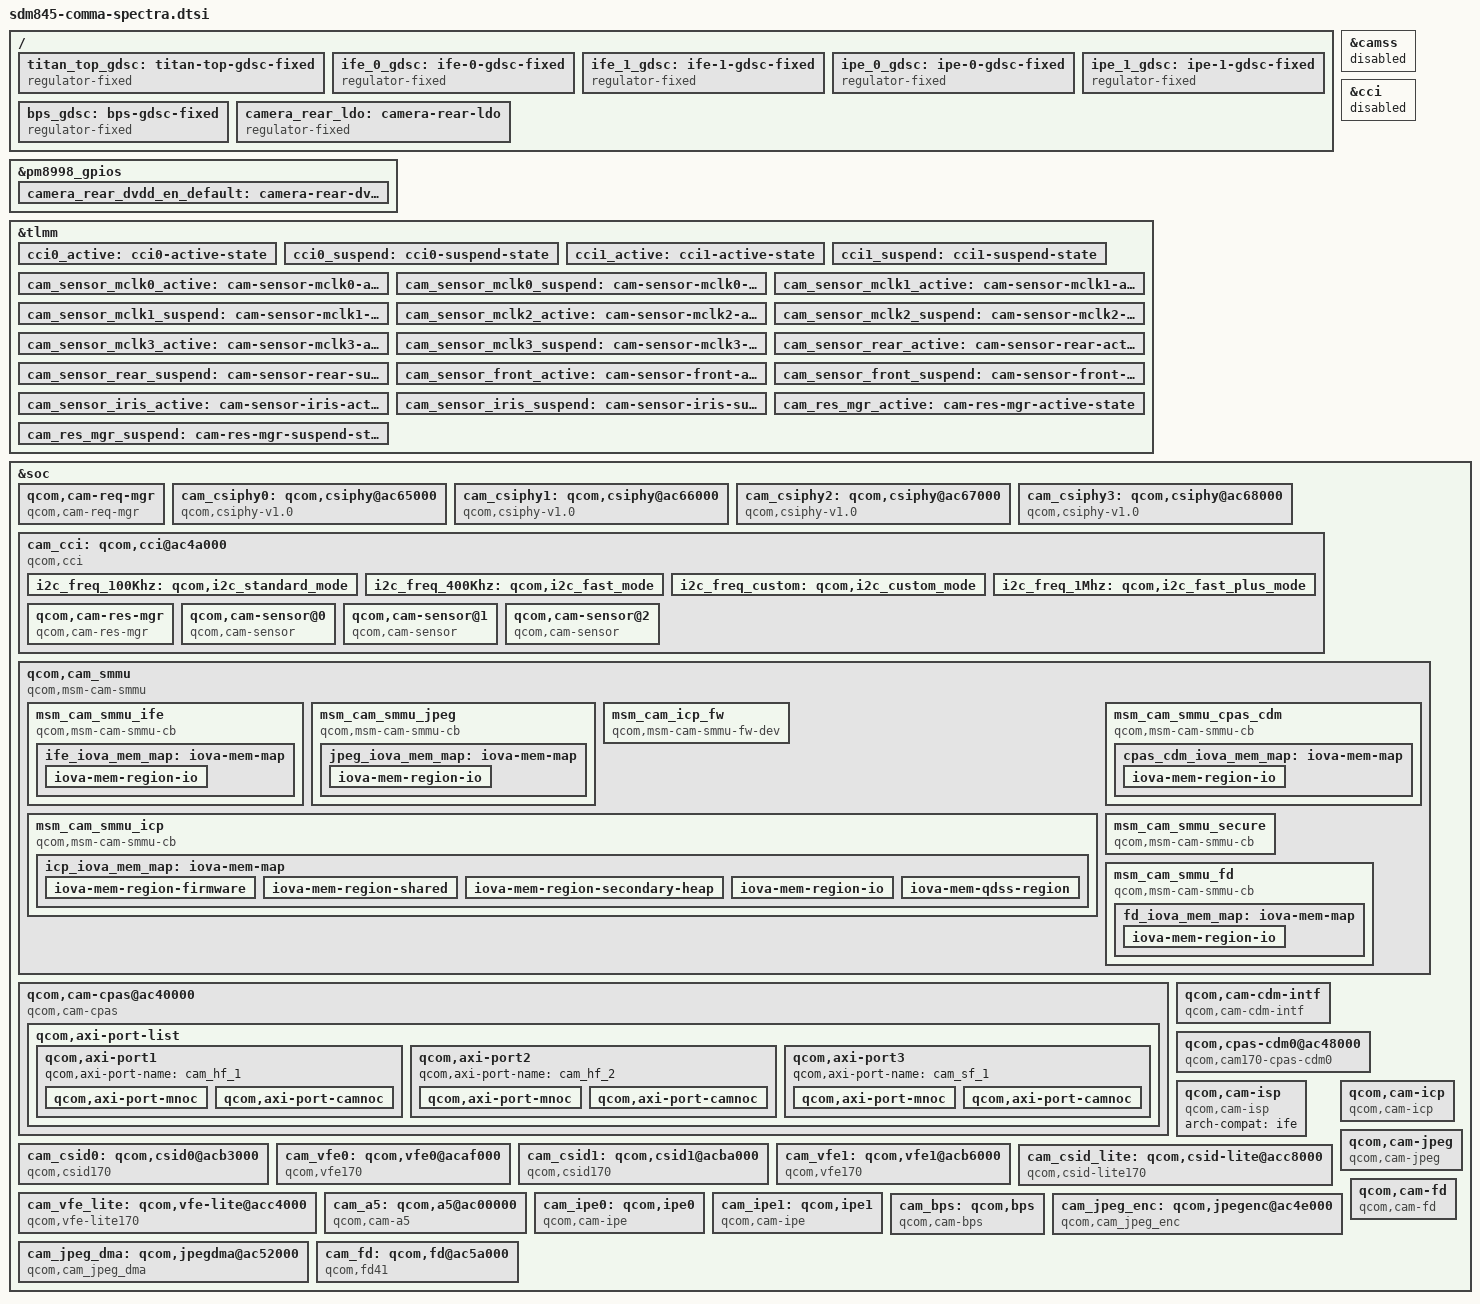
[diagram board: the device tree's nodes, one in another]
// SPDX-License-Identifier: GPL-2.0-only
// Camera-only nodes from cameras-spectra-mainline-andi, 391dedc767d9.

#include <dt-bindings/clock/qcom,camcc-sdm845.h>
#include <dt-bindings/clock/qcom,gcc-sdm845.h>
#include <dt-bindings/clock/qcom,rpmh.h>
#include <dt-bindings/gpio/gpio.h>
#include <dt-bindings/interconnect/qcom,icc.h>
#include <dt-bindings/interconnect/qcom,sdm845.h>
#include <dt-bindings/interrupt-controller/arm-gic.h>
#include <dt-bindings/pinctrl/qcom,pmic-gpio.h>

/ {
	titan_top_gdsc: titan-top-gdsc-fixed {
		compatible = "regulator-fixed";
		regulator-name = "titan_top_gdsc";
		regulator-always-on;
		regulator-boot-on;
	};

	ife_0_gdsc: ife-0-gdsc-fixed {
		compatible = "regulator-fixed";
		regulator-name = "ife_0_gdsc";
		regulator-always-on;
		regulator-boot-on;
	};

	ife_1_gdsc: ife-1-gdsc-fixed {
		compatible = "regulator-fixed";
		regulator-name = "ife_1_gdsc";
		regulator-always-on;
		regulator-boot-on;
	};

	ipe_0_gdsc: ipe-0-gdsc-fixed {
		compatible = "regulator-fixed";
		regulator-name = "ipe_0_gdsc";
		regulator-always-on;
		regulator-boot-on;
	};

	ipe_1_gdsc: ipe-1-gdsc-fixed {
		compatible = "regulator-fixed";
		regulator-name = "ipe_1_gdsc";
		regulator-always-on;
		regulator-boot-on;
	};

	bps_gdsc: bps-gdsc-fixed {
		compatible = "regulator-fixed";
		regulator-name = "bps_gdsc";
		regulator-always-on;
		regulator-boot-on;
	};

	camera_rear_ldo: camera-rear-ldo {
		compatible = "regulator-fixed";
		regulator-name = "camera_rear_ldo";
		regulator-min-microvolt = <1050000>;
		regulator-max-microvolt = <1050000>;
		gpio = <&pm8998_gpios 12 GPIO_ACTIVE_HIGH>;
		enable-active-high;
		pinctrl-names = "default";
		pinctrl-0 = <&camera_rear_dvdd_en_default>;
		regulator-always-on;
		regulator-boot-on;
	};






};
&camss {
	status = "disabled";
};

&cci {
	status = "disabled";
};

&pm8998_gpios {

	camera_rear_dvdd_en_default: camera-rear-dvdd-en-state {
		pins = "gpio12";
		function = "normal";
		bias-disable;
		drive-push-pull;
		qcom,drive-strength = <PMIC_GPIO_STRENGTH_HIGH>;
		output-high;
	};


};

&tlmm {
	cci0_active: cci0-active-state {
		pins = "gpio17", "gpio18";
		function = "cci_i2c";
		bias-pull-up;
		drive-strength = <2>;
	};

	cci0_suspend: cci0-suspend-state {
		pins = "gpio17", "gpio18";
		function = "cci_i2c";
		bias-pull-down;
		drive-strength = <2>;
	};

	cci1_active: cci1-active-state {
		pins = "gpio19", "gpio20";
		function = "cci_i2c";
		bias-pull-up;
		drive-strength = <2>;
	};

	cci1_suspend: cci1-suspend-state {
		pins = "gpio19", "gpio20";
		function = "cci_i2c";
		bias-pull-down;
		drive-strength = <2>;
	};

	cam_sensor_mclk0_active: cam-sensor-mclk0-active-state {
		pins = "gpio13";
		function = "cam_mclk";
		bias-disable;
		drive-strength = <8>;
	};

	cam_sensor_mclk0_suspend: cam-sensor-mclk0-suspend-state {
		pins = "gpio13";
		function = "cam_mclk";
		bias-pull-down;
		drive-strength = <8>;
	};

	cam_sensor_mclk1_active: cam-sensor-mclk1-active-state {
		pins = "gpio14";
		function = "cam_mclk";
		bias-disable;
		drive-strength = <8>;
	};

	cam_sensor_mclk1_suspend: cam-sensor-mclk1-suspend-state {
		pins = "gpio14";
		function = "cam_mclk";
		bias-pull-down;
		drive-strength = <8>;
	};

	cam_sensor_mclk2_active: cam-sensor-mclk2-active-state {
		pins = "gpio15";
		function = "cam_mclk";
		bias-disable;
		drive-strength = <8>;
	};

	cam_sensor_mclk2_suspend: cam-sensor-mclk2-suspend-state {
		pins = "gpio15";
		function = "cam_mclk";
		bias-pull-down;
		drive-strength = <8>;
	};

	cam_sensor_mclk3_active: cam-sensor-mclk3-active-state {
		pins = "gpio16";
		function = "cam_mclk";
		bias-disable;
		drive-strength = <2>;
	};

	cam_sensor_mclk3_suspend: cam-sensor-mclk3-suspend-state {
		pins = "gpio16";
		function = "cam_mclk";
		bias-pull-down;
		drive-strength = <2>;
	};

	cam_sensor_rear_active: cam-sensor-rear-active-state {
		pins = "gpio9";
		function = "gpio";
		bias-disable;
		drive-strength = <2>;
	};

	cam_sensor_rear_suspend: cam-sensor-rear-suspend-state {
		pins = "gpio9";
		function = "gpio";
		bias-pull-down;
		drive-strength = <2>;
		output-low;
	};

	cam_sensor_front_active: cam-sensor-front-active-state {
		pins = "gpio28";
		function = "gpio";
		bias-disable;
		drive-strength = <2>;
	};

	cam_sensor_front_suspend: cam-sensor-front-suspend-state {
		pins = "gpio28";
		function = "gpio";
		bias-pull-down;
		drive-strength = <2>;
		output-low;
	};

	cam_sensor_iris_active: cam-sensor-iris-active-state {
		pins = "gpio21";
		function = "gpio";
		bias-disable;
		drive-strength = <2>;
	};

	cam_sensor_iris_suspend: cam-sensor-iris-suspend-state {
		pins = "gpio21";
		function = "gpio";
		bias-pull-down;
		drive-strength = <2>;
		output-low;
	};

	cam_res_mgr_active: cam-res-mgr-active-state {
		pins = "gpio8";
		function = "gpio";
		bias-disable;
		drive-strength = <2>;
	};

	cam_res_mgr_suspend: cam-res-mgr-suspend-state {
		pins = "gpio8";
		function = "gpio";
		bias-disable;
		drive-strength = <2>;
		output-low;
	};
};

&soc {
	#address-cells = <2>;
	#size-cells = <2>;
	qcom,cam-req-mgr {
		compatible = "qcom,cam-req-mgr";
		status = "ok";
	};

	cam_csiphy0: qcom,csiphy@ac65000 {
		cell-index = <0>;
		compatible = "qcom,csiphy-v1.0", "qcom,csiphy";
		reg = <0 0x0ac65000 0 0x1000>;
		reg-names = "csiphy";
		reg-cam-base = <0x65000>;
		interrupts = <GIC_SPI 477 IRQ_TYPE_EDGE_RISING>;
		interrupt-names = "csiphy";
		gdscr-supply = <&titan_top_gdsc>;
		regulator-names = "gdscr";
		csi-vdd-voltage = <1200000>;
		mipi-csi-vdd-supply = <&vreg_l1a_0p875>;
		clocks = <&clock_camcc CAM_CC_CAMNOC_AXI_CLK>,
			<&clock_camcc CAM_CC_SOC_AHB_CLK>,
			<&clock_camcc CAM_CC_SLOW_AHB_CLK_SRC>,
			<&clock_camcc CAM_CC_CPAS_AHB_CLK>,
			<&clock_camcc CAM_CC_CPHY_RX_CLK_SRC>,
			<&clock_camcc CAM_CC_CSIPHY0_CLK>,
			<&clock_camcc CAM_CC_CSI0PHYTIMER_CLK_SRC>,
			<&clock_camcc CAM_CC_CSI0PHYTIMER_CLK>;
		clock-names = "camnoc_axi_clk",
			"soc_ahb_clk",
			"slow_ahb_src_clk",
			"cpas_ahb_clk",
			"cphy_rx_clk_src",
			"csiphy0_clk",
			"csi0phytimer_clk_src",
			"csi0phytimer_clk";
		src-clock-name = "csi0phytimer_clk_src";
		clock-cntl-level = "svs", "turbo";
		clock-rates =
			<0 0 0 0 320000000 0 269333333 0>,
			<0 0 0 0 384000000 0 269333333 0>;
		status = "ok";
	};

	cam_csiphy1: qcom,csiphy@ac66000 {
		cell-index = <1>;
		compatible = "qcom,csiphy-v1.0", "qcom,csiphy";
		reg = <0 0x0ac66000 0 0x1000>;
		reg-names = "csiphy";
		reg-cam-base = <0x66000>;
		interrupts = <GIC_SPI 478 IRQ_TYPE_EDGE_RISING>;
		interrupt-names = "csiphy";
		gdscr-supply = <&titan_top_gdsc>;
		regulator-names = "gdscr";
		csi-vdd-voltage = <1200000>;
		mipi-csi-vdd-supply = <&vreg_l1a_0p875>;
		clocks = <&clock_camcc CAM_CC_CAMNOC_AXI_CLK>,
			<&clock_camcc CAM_CC_SOC_AHB_CLK>,
			<&clock_camcc CAM_CC_SLOW_AHB_CLK_SRC>,
			<&clock_camcc CAM_CC_CPAS_AHB_CLK>,
			<&clock_camcc CAM_CC_CPHY_RX_CLK_SRC>,
			<&clock_camcc CAM_CC_CSIPHY1_CLK>,
			<&clock_camcc CAM_CC_CSI1PHYTIMER_CLK_SRC>,
			<&clock_camcc CAM_CC_CSI1PHYTIMER_CLK>;
		clock-names = "camnoc_axi_clk",
			"soc_ahb_clk",
			"slow_ahb_src_clk",
			"cpas_ahb_clk",
			"cphy_rx_clk_src",
			"csiphy1_clk",
			"csi1phytimer_clk_src",
			"csi1phytimer_clk";
		src-clock-name = "csi1phytimer_clk_src";
		clock-cntl-level = "svs", "turbo";
		clock-rates =
			<0 0 0 0 320000000 0 269333333 0>,
			<0 0 0 0 384000000 0 269333333 0>;
		status = "ok";
	};

	cam_csiphy2: qcom,csiphy@ac67000 {
		cell-index = <2>;
		compatible = "qcom,csiphy-v1.0", "qcom,csiphy";
		reg = <0 0x0ac67000 0 0x1000>;
		reg-names = "csiphy";
		reg-cam-base = <0x67000>;
		interrupts = <GIC_SPI 479 IRQ_TYPE_EDGE_RISING>;
		interrupt-names = "csiphy";
		gdscr-supply = <&titan_top_gdsc>;
		regulator-names = "gdscr";
		csi-vdd-voltage = <1200000>;
		mipi-csi-vdd-supply = <&vreg_l1a_0p875>;
		clocks = <&clock_camcc CAM_CC_CAMNOC_AXI_CLK>,
			<&clock_camcc CAM_CC_SOC_AHB_CLK>,
			<&clock_camcc CAM_CC_SLOW_AHB_CLK_SRC>,
			<&clock_camcc CAM_CC_CPAS_AHB_CLK>,
			<&clock_camcc CAM_CC_CPHY_RX_CLK_SRC>,
			<&clock_camcc CAM_CC_CSIPHY2_CLK>,
			<&clock_camcc CAM_CC_CSI2PHYTIMER_CLK_SRC>,
			<&clock_camcc CAM_CC_CSI2PHYTIMER_CLK>;
		clock-names = "camnoc_axi_clk",
			"soc_ahb_clk",
			"slow_ahb_src_clk",
			"cpas_ahb_clk",
			"cphy_rx_clk_src",
			"csiphy2_clk",
			"csi2phytimer_clk_src",
			"csi2phytimer_clk";
		src-clock-name = "csi2phytimer_clk_src";
		clock-cntl-level = "svs", "turbo";
		clock-rates =
			<0 0 0 0 320000000 0 269333333 0>,
			<0 0 0 0 384000000 0 269333333 0>;
		status = "ok";
	};

	cam_csiphy3: qcom,csiphy@ac68000 {
		cell-index = <3>;
		compatible = "qcom,csiphy-v1.0", "qcom,csiphy";
		reg = <0 0x0ac68000 0 0x1000>;
		reg-names = "csiphy";
		reg-cam-base = <0x68000>;
		interrupts = <GIC_SPI 448 IRQ_TYPE_EDGE_RISING>;
		interrupt-names = "csiphy";
		gdscr-supply = <&titan_top_gdsc>;
		regulator-names = "gdscr";
		csi-vdd-voltage = <1200000>;
		mipi-csi-vdd-supply = <&vreg_l1a_0p875>;
		clocks = <&clock_camcc CAM_CC_CAMNOC_AXI_CLK>,
			<&clock_camcc CAM_CC_SOC_AHB_CLK>,
			<&clock_camcc CAM_CC_SLOW_AHB_CLK_SRC>,
			<&clock_camcc CAM_CC_CPAS_AHB_CLK>,
			<&clock_camcc CAM_CC_CPHY_RX_CLK_SRC>,
			<&clock_camcc CAM_CC_CSIPHY3_CLK>,
			<&clock_camcc CAM_CC_CSI3PHYTIMER_CLK_SRC>,
			<&clock_camcc CAM_CC_CSI3PHYTIMER_CLK>;
		clock-names = "camnoc_axi_clk",
			"soc_ahb_clk",
			"slow_ahb_src_clk",
			"cpas_ahb_clk",
			"cphy_rx_clk_src",
			"csiphy3_clk",
			"csi3phytimer_clk_src",
			"csi3phytimer_clk";
		src-clock-name = "csi3phytimer_clk_src";
		clock-cntl-level = "svs", "turbo";
		clock-rates =
			<0 0 0 0 320000000 0 269333333 0>,
			<0 0 0 0 384000000 0 269333333 0>;
		status = "ok";
	};

	cam_cci: qcom,cci@ac4a000 {
		cell-index = <0>;
		compatible = "qcom,cci";
		#address-cells = <1>;
		#size-cells = <0>;
		reg = <0 0x0ac4a000 0 0x4000>;
		reg-names = "cci";
		reg-cam-base = <0x4a000>;
		interrupt-names = "cci";
		interrupts = <GIC_SPI 460 IRQ_TYPE_EDGE_RISING>;
		status = "ok";
		gdscr-supply = <&titan_top_gdsc>;
		regulator-names = "gdscr";
		clocks = <&clock_camcc CAM_CC_CAMNOC_AXI_CLK>,
			<&clock_camcc CAM_CC_SOC_AHB_CLK>,
			<&clock_camcc CAM_CC_SLOW_AHB_CLK_SRC>,
			<&clock_camcc CAM_CC_CPAS_AHB_CLK>,
			<&clock_camcc CAM_CC_CCI_CLK>,
			<&clock_camcc CAM_CC_CCI_CLK_SRC>;
		clock-names = "camnoc_axi_clk",
			"soc_ahb_clk",
			"slow_ahb_src_clk",
			"cpas_ahb_clk",
			"cci_clk",
			"cci_clk_src";
		src-clock-name = "cci_clk_src";
		clock-cntl-level = "lowsvs";
		clock-rates = <0 0 0 0 0 37500000>;
		pinctrl-names = "cam_default", "cam_suspend";

		pinctrl-0 = <&cci0_active &cci1_active
			     &cam_sensor_mclk0_active
			     &cam_sensor_mclk1_active
			     &cam_sensor_mclk2_active
			     &cam_sensor_mclk3_active>;
		pinctrl-1 = <&cci0_suspend &cci1_suspend
			     &cam_sensor_mclk0_suspend
			     &cam_sensor_mclk1_suspend
			     &cam_sensor_mclk2_suspend
			     &cam_sensor_mclk3_suspend>;
		gpios = <&tlmm 17 0>,
			<&tlmm 18 0>,
			<&tlmm 19 0>,
			<&tlmm 20 0>;
		gpio-req-tbl-num = <0 1 2 3>;
		gpio-req-tbl-flags = <1 1 1 1>;
		gpio-req-tbl-label = "CCI_I2C_DATA0",
					"CCI_I2C_CLK0",
					"CCI_I2C_DATA1",
					"CCI_I2C_CLK1";

		i2c_freq_100Khz: qcom,i2c_standard_mode {
			hw-thigh = <201>;
			hw-tlow = <174>;
			hw-tsu-sto = <204>;
			hw-tsu-sta = <231>;
			hw-thd-dat = <22>;
			hw-thd-sta = <162>;
			hw-tbuf = <227>;
			hw-scl-stretch-en = <0>;
			hw-trdhld = <6>;
			hw-tsp = <3>;
			cci-clk-src = <37500000>;
			status = "ok";
		};

		i2c_freq_400Khz: qcom,i2c_fast_mode {
			hw-thigh = <38>;
			hw-tlow = <56>;
			hw-tsu-sto = <40>;
			hw-tsu-sta = <40>;
			hw-thd-dat = <22>;
			hw-thd-sta = <35>;
			hw-tbuf = <62>;
			hw-scl-stretch-en = <0>;
			hw-trdhld = <6>;
			hw-tsp = <3>;
			cci-clk-src = <37500000>;
			status = "ok";
		};

		i2c_freq_custom: qcom,i2c_custom_mode {
			hw-thigh = <38>;
			hw-tlow = <56>;
			hw-tsu-sto = <40>;
			hw-tsu-sta = <40>;
			hw-thd-dat = <22>;
			hw-thd-sta = <35>;
			hw-tbuf = <62>;
			hw-scl-stretch-en = <1>;
			hw-trdhld = <6>;
			hw-tsp = <3>;
			cci-clk-src = <37500000>;
			status = "ok";
		};

		i2c_freq_1Mhz: qcom,i2c_fast_plus_mode {
			hw-thigh = <16>;
			hw-tlow = <22>;
			hw-tsu-sto = <17>;
			hw-tsu-sta = <18>;
			hw-thd-dat = <16>;
			hw-thd-sta = <15>;
			hw-tbuf = <24>;
			hw-scl-stretch-en = <0>;
			hw-trdhld = <3>;
			hw-tsp = <3>;
			cci-clk-src = <37500000>;
			status = "ok";
		};
	};

	qcom,cam_smmu {
		compatible = "qcom,msm-cam-smmu";
		status = "ok";

		msm_cam_smmu_ife {
			compatible = "qcom,msm-cam-smmu-cb";
			iommus = <&apps_smmu 0x808 0x0>,
				<&apps_smmu 0x810 0x8>,
				<&apps_smmu 0xc08 0x0>,
				<&apps_smmu 0xc10 0x8>;
			label = "ife";
			ife_iova_mem_map: iova-mem-map {
				iova-mem-region-io {
					iova-region-name = "io";
					iova-region-start = <0x7400000>;
					iova-region-len = <0xd8c00000>;
					iova-region-id = <0x3>;
					status = "ok";
				};
			};
		};

		msm_cam_smmu_jpeg {
			compatible = "qcom,msm-cam-smmu-cb";
			iommus = <&apps_smmu 0x1060 0x8>,
				<&apps_smmu 0x1068 0x8>;
			label = "jpeg";
			jpeg_iova_mem_map: iova-mem-map {
				iova-mem-region-io {
					iova-region-name = "io";
					iova-region-start = <0x7400000>;
					iova-region-len = <0xd8c00000>;
					iova-region-id = <0x3>;
					status = "ok";
				};
			};
		};

		msm_cam_icp_fw {
			compatible = "qcom,msm-cam-smmu-fw-dev";
			label = "icp";
			memory-region = <&camera_mem>;
		};

		msm_cam_smmu_icp {
			compatible = "qcom,msm-cam-smmu-cb";
			iommus = <&apps_smmu 0x1078 0x2>,
				<&apps_smmu 0x1020 0x8>,
				<&apps_smmu 0x1040 0x8>,
				<&apps_smmu 0x1030 0x0>,
				<&apps_smmu 0x1050 0x0>;
			label = "icp";
			icp_iova_mem_map: iova-mem-map {
				iova-mem-region-firmware {
					iova-region-name = "firmware";
					iova-region-start = <0x0>;

					iova-region-len = <0x400000>;
					iova-region-id = <0x0>;
					status = "ok";
				};

				iova-mem-region-shared {
					iova-region-name = "shared";
					iova-region-start = <0x7400000>;
					iova-region-len = <0x6400000>;
					iova-region-id = <0x1>;
					status = "ok";
				};

				iova-mem-region-secondary-heap {
					iova-region-name = "secheap";
					iova-region-start = <0xd800000>;
					iova-region-len = <0x100000>;
					iova-region-id = <0x4>;
					status = "ok";
				};

				iova-mem-region-io {
					iova-region-name = "io";
					iova-region-start = <0xda00000>;
					iova-region-len = <0xd2500000>;
					iova-region-id = <0x3>;
					status = "ok";
				};

				iova-mem-qdss-region {
					iova-region-name = "qdss";
					iova-region-start = <0xd900000>;
					iova-region-len = <0x100000>;
					iova-region-id = <0x5>;
					qdss-phy-addr = <0x16790000>;
					status = "ok";
				};
			};
		};

		msm_cam_smmu_cpas_cdm {
			compatible = "qcom,msm-cam-smmu-cb";
			iommus = <&apps_smmu 0x1000 0x0>;
			label = "cpas-cdm0";
			cpas_cdm_iova_mem_map: iova-mem-map {
				iova-mem-region-io {
					iova-region-name = "io";
					iova-region-start = <0x7400000>;
					iova-region-len = <0xd8c00000>;
					iova-region-id = <0x3>;
					status = "ok";
				};
			};
		};

		msm_cam_smmu_secure {
			compatible = "qcom,msm-cam-smmu-cb";
			label = "cam-secure";
			qcom,secure-cb;
		};

		msm_cam_smmu_fd {
			compatible = "qcom,msm-cam-smmu-cb";
			iommus = <&apps_smmu 0x1070 0x0>;
			label = "fd";
			fd_iova_mem_map: iova-mem-map {
				iova-mem-region-io {
					iova-region-name = "io";
					iova-region-start = <0x7400000>;
					iova-region-len = <0xd8c00000>;
					iova-region-id = <0x3>;
					status = "ok";
				};
			};
		};
	};

	qcom,cam-cpas@ac40000 {
		cell-index = <0>;
		compatible = "qcom,cam-cpas";
		label = "cpas";
		arch-compat = "cpas_top";
		status = "ok";
		reg-names = "cam_cpas_top", "cam_camnoc";
		reg = <0 0x0ac40000 0 0x1000>,
			<0 0x0ac42000 0 0x5000>;
		reg-cam-base = <0x40000 0x42000>;
		interrupt-names = "cpas_camnoc";
		interrupts = <GIC_SPI 459 IRQ_TYPE_EDGE_RISING>;
		qcom,cpas-hw-ver = <0x170100>;
		camnoc-axi-min-ib-bw = <3000000000>;
		regulator-names = "camss-vdd";
		camss-vdd-supply = <&titan_top_gdsc>;
		power-domains = <&clock_camcc TITAN_TOP_GDSC>;
		clock-names = "gcc_ahb_clk",
			"gcc_axi_clk",
			"soc_ahb_clk",
			"slow_ahb_clk_src",
			"cpas_ahb_clk",
			"camnoc_axi_clk";
		clocks = <&gcc GCC_CAMERA_AHB_CLK>,
			<&gcc GCC_CAMERA_AXI_CLK>,
			<&clock_camcc CAM_CC_SOC_AHB_CLK>,
			<&clock_camcc CAM_CC_SLOW_AHB_CLK_SRC>,
			<&clock_camcc CAM_CC_CPAS_AHB_CLK>,
			<&clock_camcc CAM_CC_CAMNOC_AXI_CLK>;
		src-clock-name = "slow_ahb_clk_src";
		clock-rates = <0 0 0 0 0 0>,
			<0 0 0 19200000 0 0>,
			<0 0 0 60000000 0 0>,
			<0 0 0 66660000 0 0>,
			<0 0 0 73840000 0 0>,
			<0 0 0 80000000 0 0>,
			<0 0 0 80000000 0 0>;
		clock-cntl-level = "suspend", "minsvs", "lowsvs", "svs",
			"svs_l1", "nominal", "turbo";

		client-id-based;

		client-names =
			"csiphy0", "csiphy1", "csiphy2", "csiphy3", "cci0",
			"csid0", "csid1", "csid2",
			"ife0", "ife1", "ife2", "ipe0",
			"ipe1", "cam-cdm-intf0", "cpas-cdm0", "bps0",
			"icp0", "jpeg-dma0", "jpeg-enc0", "fd0", "lrmecpas";
		client-axi-port-names =
			"cam_hf_1", "cam_hf_2", "cam_hf_2", "cam_hf_1", "cam_sf_1",
			"cam_hf_1", "cam_hf_2", "cam_hf_2",
			"cam_hf_1", "cam_hf_2", "cam_hf_2", "cam_sf_1",
			"cam_sf_1", "cam_sf_1", "cam_sf_1", "cam_sf_1",
			"cam_sf_1", "cam_sf_1", "cam_sf_1", "cam_sf_1",
			"cam_sf_1";
		client-bus-camnoc-based;
		qcom,axi-port-list {
			qcom,axi-port1 {
				qcom,axi-port-name = "cam_hf_1";
				qcom,axi-port-mnoc {
					qcom,msm-bus,name = "cam_hf_1_mnoc";
					qcom,msm-bus-vector-dyn-vote;
				};
				qcom,axi-port-camnoc {
					qcom,msm-bus,name = "cam_hf_1_camnoc";
					qcom,msm-bus-vector-dyn-vote;
				};
			};
			qcom,axi-port2 {
				qcom,axi-port-name = "cam_hf_2";
				qcom,axi-port-mnoc {
					qcom,msm-bus,name = "cam_hf_2_mnoc";
					qcom,msm-bus-vector-dyn-vote;
				};
				qcom,axi-port-camnoc {
					qcom,msm-bus,name = "cam_hf_2_camnoc";
					qcom,msm-bus-vector-dyn-vote;
				};
			};
			qcom,axi-port3 {
				qcom,axi-port-name = "cam_sf_1";
				qcom,axi-port-mnoc {
					qcom,msm-bus,name = "cam_sf_1_mnoc";
					qcom,msm-bus-vector-dyn-vote;
				};
				qcom,axi-port-camnoc {
					qcom,msm-bus,name = "cam_sf_1_camnoc";
					qcom,msm-bus-vector-dyn-vote;
				};
			};
		};
	};

	qcom,cam-cdm-intf {
		compatible = "qcom,cam-cdm-intf";
		cell-index = <0>;
		label = "cam-cdm-intf";
		num-hw-cdm = <1>;
		cdm-client-names = "vfe",
			"jpegdma",
			"jpegenc",
			"fd",
			"lrmecdm";
		status = "ok";
	};

	qcom,cpas-cdm0@ac48000 {
		cell-index = <0>;
		compatible = "qcom,cam170-cpas-cdm0";
		label = "cpas-cdm";
		reg = <0 0x0ac48000 0 0x1000>;
		reg-names = "cpas-cdm";
		reg-cam-base = <0x48000>;
		interrupts = <GIC_SPI 461 IRQ_TYPE_EDGE_RISING>;
		interrupt-names = "cpas-cdm";
		regulator-names = "camss";
		camss-supply = <&titan_top_gdsc>;
		clock-names = "gcc_camera_ahb",
			"gcc_camera_axi",
			"cam_cc_soc_ahb_clk",
			"cam_cc_cpas_ahb_clk",
			"cam_cc_camnoc_axi_clk";
		clocks = <&gcc GCC_CAMERA_AHB_CLK>,
			<&gcc GCC_CAMERA_AXI_CLK>,
			<&clock_camcc CAM_CC_SOC_AHB_CLK>,
			<&clock_camcc CAM_CC_CPAS_AHB_CLK>,
			<&clock_camcc CAM_CC_CAMNOC_AXI_CLK>;
		clock-rates = <0 0 0 0 0>;
		clock-cntl-level = "svs";
		cdm-client-names = "ife";
		status = "ok";
	};

	qcom,cam-isp {
		compatible = "qcom,cam-isp";
		arch-compat = "ife";
		status = "ok";
	};

	cam_csid0: qcom,csid0@acb3000 {
		cell-index = <0>;
		compatible = "qcom,csid170";
		reg-names = "csid";
		reg = <0 0x0acb3000 0 0x1000>;
		reg-cam-base = <0xb3000>;
		interrupt-names = "csid";
		interrupts = <GIC_SPI 464 IRQ_TYPE_EDGE_RISING>;
		regulator-names = "camss", "ife0";
		camss-supply = <&titan_top_gdsc>;
		ife0-supply = <&ife_0_gdsc>;

		power-domains = <&clock_camcc IFE_0_GDSC>;
		clock-names = "camera_ahb",
			"camera_axi",
			"soc_ahb_clk",
			"cpas_ahb_clk",
			"slow_ahb_clk_src",
			"ife_csid_clk",
			"ife_csid_clk_src",
			"ife_cphy_rx_clk",
			"cphy_rx_clk_src",
			"ife_clk",
			"ife_clk_src",
			"camnoc_axi_clk",
			"ife_axi_clk";
		clocks = <&gcc GCC_CAMERA_AHB_CLK>,
			<&gcc GCC_CAMERA_AXI_CLK>,
			<&clock_camcc CAM_CC_SOC_AHB_CLK>,
			<&clock_camcc CAM_CC_CPAS_AHB_CLK>,
			<&clock_camcc CAM_CC_SLOW_AHB_CLK_SRC>,
			<&clock_camcc CAM_CC_IFE_0_CSID_CLK>,
			<&clock_camcc CAM_CC_IFE_0_CSID_CLK_SRC>,
			<&clock_camcc CAM_CC_IFE_0_CPHY_RX_CLK>,
			<&clock_camcc CAM_CC_CPHY_RX_CLK_SRC>,
			<&clock_camcc CAM_CC_IFE_0_CLK>,
			<&clock_camcc CAM_CC_IFE_0_CLK_SRC>,
			<&clock_camcc CAM_CC_CAMNOC_AXI_CLK>,
			<&clock_camcc CAM_CC_IFE_0_AXI_CLK>;
		clock-rates =
			<0 0 0 0 0 0 384000000 0 0 0 404000000 0 0>,
			<0 0 0 0 0 0 538000000 0 0 0 600000000 0 0>;
		clock-cntl-level = "svs", "turbo";
		src-clock-name = "ife_csid_clk_src";
		clock-control-debugfs = "true";
		status = "ok";
	};

	cam_vfe0: qcom,vfe0@acaf000 {
		cell-index = <0>;
		compatible = "qcom,vfe170";
		reg-names = "ife";
		reg = <0 0x0acaf000 0 0x4000>;
		reg-cam-base = <0xaf000>;
		interrupt-names = "ife";
		interrupts = <GIC_SPI 465 IRQ_TYPE_EDGE_RISING>;
		regulator-names = "camss", "ife0";
		camss-supply = <&titan_top_gdsc>;
		ife0-supply = <&ife_0_gdsc>;

		power-domains = <&clock_camcc IFE_0_GDSC>;
		clock-names = "camera_ahb",
			"camera_axi",
			"soc_ahb_clk",
			"cpas_ahb_clk",
			"slow_ahb_clk_src",
			"ife_clk",
			"ife_clk_src",
			"camnoc_axi_clk",
			"ife_axi_clk";
		clocks = <&gcc GCC_CAMERA_AHB_CLK>,
			<&gcc GCC_CAMERA_AXI_CLK>,
			<&clock_camcc CAM_CC_SOC_AHB_CLK>,
			<&clock_camcc CAM_CC_CPAS_AHB_CLK>,
			<&clock_camcc CAM_CC_SLOW_AHB_CLK_SRC>,
			<&clock_camcc CAM_CC_IFE_0_CLK>,
			<&clock_camcc CAM_CC_IFE_0_CLK_SRC>,
			<&clock_camcc CAM_CC_CAMNOC_AXI_CLK>,
			<&clock_camcc CAM_CC_IFE_0_AXI_CLK>;
		clock-rates =
			<0 0 0 0 0 0 404000000 0 0>,
			<0 0 0 0 0 0 480000000 0 0>,
			<0 0 0 0 0 0 600000000 0 0>;
		clock-cntl-level = "svs", "svs_l1", "turbo";
		src-clock-name = "ife_clk_src";
		clock-control-debugfs = "true";
		clock-names-option = "ife_dsp_clk";
		clocks-option = <&clock_camcc CAM_CC_IFE_0_DSP_CLK>;
		clock-rates-option = <600000000>;
		status = "ok";
	};

	cam_csid1: qcom,csid1@acba000 {
		cell-index = <1>;
		compatible = "qcom,csid170";
		reg-names = "csid";
		reg = <0 0x0acba000 0 0x1000>;
		reg-cam-base = <0xba000>;
		interrupt-names = "csid";
		interrupts = <GIC_SPI 466 IRQ_TYPE_EDGE_RISING>;
		regulator-names = "camss", "ife1";
		camss-supply = <&titan_top_gdsc>;
		ife1-supply = <&ife_1_gdsc>;

		power-domains = <&clock_camcc IFE_1_GDSC>;
		clock-names = "camera_ahb",
			"camera_axi",
			"soc_ahb_clk",
			"cpas_ahb_clk",
			"slow_ahb_clk_src",
			"ife_csid_clk",
			"ife_csid_clk_src",
			"ife_cphy_rx_clk",
			"cphy_rx_clk_src",
			"ife_clk",
			"ife_clk_src",
			"camnoc_axi_clk",
			"ife_axi_clk";
		clocks = <&gcc GCC_CAMERA_AHB_CLK>,
			<&gcc GCC_CAMERA_AXI_CLK>,
			<&clock_camcc CAM_CC_SOC_AHB_CLK>,
			<&clock_camcc CAM_CC_CPAS_AHB_CLK>,
			<&clock_camcc CAM_CC_SLOW_AHB_CLK_SRC>,
			<&clock_camcc CAM_CC_IFE_1_CSID_CLK>,
			<&clock_camcc CAM_CC_IFE_1_CSID_CLK_SRC>,
			<&clock_camcc CAM_CC_IFE_1_CPHY_RX_CLK>,
			<&clock_camcc CAM_CC_CPHY_RX_CLK_SRC>,
			<&clock_camcc CAM_CC_IFE_1_CLK>,
			<&clock_camcc CAM_CC_IFE_1_CLK_SRC>,
			<&clock_camcc CAM_CC_CAMNOC_AXI_CLK>,
			<&clock_camcc CAM_CC_IFE_1_AXI_CLK>;
		clock-rates =
			<0 0 0 0 0 0 384000000 0 0 0 404000000 0 0>,
			<0 0 0 0 0 0 538000000 0 0 0 600000000 0 0>;
		clock-cntl-level = "svs", "turbo";
		src-clock-name = "ife_csid_clk_src";
		clock-control-debugfs = "true";
		status = "ok";
	};

	cam_vfe1: qcom,vfe1@acb6000 {
		cell-index = <1>;
		compatible = "qcom,vfe170";
		reg-names = "ife";
		reg = <0 0x0acb6000 0 0x4000>;
		reg-cam-base = <0xb6000>;
		interrupt-names = "ife";
		interrupts = <GIC_SPI 467 IRQ_TYPE_EDGE_RISING>;
		regulator-names = "camss", "ife1";
		camss-supply = <&titan_top_gdsc>;
		ife1-supply = <&ife_1_gdsc>;

		power-domains = <&clock_camcc IFE_1_GDSC>;
		clock-names = "camera_ahb",
			"camera_axi",
			"soc_ahb_clk",
			"cpas_ahb_clk",
			"slow_ahb_clk_src",
			"ife_clk",
			"ife_clk_src",
			"camnoc_axi_clk",
			"ife_axi_clk";
		clocks = <&gcc GCC_CAMERA_AHB_CLK>,
			<&gcc GCC_CAMERA_AXI_CLK>,
			<&clock_camcc CAM_CC_SOC_AHB_CLK>,
			<&clock_camcc CAM_CC_CPAS_AHB_CLK>,
			<&clock_camcc CAM_CC_SLOW_AHB_CLK_SRC>,
			<&clock_camcc CAM_CC_IFE_1_CLK>,
			<&clock_camcc CAM_CC_IFE_1_CLK_SRC>,
			<&clock_camcc CAM_CC_CAMNOC_AXI_CLK>,
			<&clock_camcc CAM_CC_IFE_1_AXI_CLK>;
		clock-rates =
			<0 0 0 0 0 0 404000000 0 0>,
			<0 0 0 0 0 0 480000000 0 0>,
			<0 0 0 0 0 0 600000000 0 0>;
		clock-cntl-level = "svs", "svs_l1", "turbo";
		src-clock-name = "ife_clk_src";
		clock-control-debugfs = "true";
		clock-names-option = "ife_dsp_clk";
		clocks-option = <&clock_camcc CAM_CC_IFE_1_DSP_CLK>;
		clock-rates-option = <600000000>;
		status = "ok";
	};

	cam_csid_lite: qcom,csid-lite@acc8000 {
		cell-index = <2>;
		compatible = "qcom,csid-lite170";
		reg-names = "csid-lite";
		reg = <0 0x0acc8000 0 0x1000>;
		reg-cam-base = <0xc8000>;
		interrupt-names = "csid-lite";
		interrupts = <GIC_SPI 468 IRQ_TYPE_EDGE_RISING>;
		regulator-names = "camss";
		camss-supply = <&titan_top_gdsc>;

		power-domains = <&clock_camcc TITAN_TOP_GDSC>;
		clock-names = "camera_ahb",
			"camera_axi",
			"soc_ahb_clk",
			"cpas_ahb_clk",
			"slow_ahb_clk_src",
			"ife_csid_clk",
			"ife_csid_clk_src",
			"ife_cphy_rx_clk",
			"cphy_rx_clk_src",
			"ife_clk",
			"ife_clk_src",
			"camnoc_axi_clk";
		clocks = <&gcc GCC_CAMERA_AHB_CLK>,
			<&gcc GCC_CAMERA_AXI_CLK>,
			<&clock_camcc CAM_CC_SOC_AHB_CLK>,
			<&clock_camcc CAM_CC_CPAS_AHB_CLK>,
			<&clock_camcc CAM_CC_SLOW_AHB_CLK_SRC>,
			<&clock_camcc CAM_CC_IFE_LITE_CSID_CLK>,
			<&clock_camcc CAM_CC_IFE_LITE_CSID_CLK_SRC>,
			<&clock_camcc CAM_CC_IFE_LITE_CPHY_RX_CLK>,
			<&clock_camcc CAM_CC_CPHY_RX_CLK_SRC>,
			<&clock_camcc CAM_CC_IFE_LITE_CLK>,
			<&clock_camcc CAM_CC_IFE_LITE_CLK_SRC>,
			<&clock_camcc CAM_CC_CAMNOC_AXI_CLK>;
		clock-rates =
			<0 0 0 0 0 0 384000000 0 0 0 404000000 0>,
			<0 0 0 0 0 0 538000000 0 0 0 600000000 0>;
		clock-cntl-level = "svs", "turbo";
		src-clock-name = "ife_csid_clk_src";
		clock-control-debugfs = "true";
		status = "ok";
	};

	cam_vfe_lite: qcom,vfe-lite@acc4000 {
		cell-index = <2>;
		compatible = "qcom,vfe-lite170";
		reg-names = "ife-lite";
		reg = <0 0x0acc4000 0 0x4000>;
		reg-cam-base = <0xc4000>;
		interrupt-names = "ife-lite";
		interrupts = <GIC_SPI 469 IRQ_TYPE_EDGE_RISING>;
		regulator-names = "camss";
		camss-supply = <&titan_top_gdsc>;

		power-domains = <&clock_camcc TITAN_TOP_GDSC>;
		clock-names = "camera_ahb",
			"camera_axi",
			"soc_ahb_clk",
			"cpas_ahb_clk",
			"slow_ahb_clk_src",
			"ife_clk",
			"ife_clk_src",
			"camnoc_axi_clk";
		clocks = <&gcc GCC_CAMERA_AHB_CLK>,
			<&gcc GCC_CAMERA_AXI_CLK>,
			<&clock_camcc CAM_CC_SOC_AHB_CLK>,
			<&clock_camcc CAM_CC_CPAS_AHB_CLK>,
			<&clock_camcc CAM_CC_SLOW_AHB_CLK_SRC>,
			<&clock_camcc CAM_CC_IFE_LITE_CLK>,
			<&clock_camcc CAM_CC_IFE_LITE_CLK_SRC>,
			<&clock_camcc CAM_CC_CAMNOC_AXI_CLK>;
		clock-rates =
			<0 0 0 0 0 0 404000000 0>,
			<0 0 0 0 0 0 480000000 0>,
			<0 0 0 0 0 0 600000000 0>;
		clock-cntl-level = "svs", "svs_l1", "turbo";
		src-clock-name = "ife_clk_src";
		clock-control-debugfs = "true";
		status = "ok";
	};

	qcom,cam-icp {
		compatible = "qcom,cam-icp";
		compat-hw-name = "qcom,a5",
			"qcom,ipe0",
			"qcom,ipe1",
			"qcom,bps";
		num-a5 = <1>;
		num-ipe = <2>;
		num-bps = <1>;
		status = "ok";
	};

	cam_a5: qcom,a5@ac00000 {
		cell-index = <0>;
		compatible = "qcom,cam-a5";
		reg = <0 0x0ac00000 0 0x6000>,
			<0 0x0ac10000 0 0x8000>,
			<0 0x0ac18000 0 0x3000>;
		reg-names = "a5_qgic", "a5_sierra", "a5_csr";
		reg-cam-base = <0x00000 0x10000 0x18000>;
		interrupts = <GIC_SPI 463 IRQ_TYPE_EDGE_RISING>;
		interrupt-names = "a5";
		regulator-names = "camss-vdd";
		camss-vdd-supply = <&titan_top_gdsc>;
		clock-names = "gcc_cam_ahb_clk",
			"gcc_cam_axi_clk",
			"soc_fast_ahb",
			"soc_ahb_clk",
			"cpas_ahb_clk",
			"camnoc_axi_clk",
			"icp_clk",
			"icp_clk_src";
		clocks = <&gcc GCC_CAMERA_AHB_CLK>,
				<&gcc GCC_CAMERA_AXI_CLK>,
				<&clock_camcc CAM_CC_FAST_AHB_CLK_SRC>,
				<&clock_camcc CAM_CC_SOC_AHB_CLK>,
				<&clock_camcc CAM_CC_CPAS_AHB_CLK>,
				<&clock_camcc CAM_CC_CAMNOC_AXI_CLK>,
				<&clock_camcc CAM_CC_ICP_CLK>,
				<&clock_camcc CAM_CC_ICP_CLK_SRC>;
		clock-rates =
			<0 0 200000000 0 0 0 0 400000000>,
			<0 0 200000000 0 0 0 0 600000000>;
		clock-cntl-level = "svs", "turbo";
		fw_name = "CAMERA_ICP.elf";
		ubwc-cfg = <0x7B 0x1EF>;
		status = "ok";
	};

	cam_ipe0: qcom,ipe0 {
		cell-index = <0>;
		compatible = "qcom,cam-ipe";
		reg = <0 0x0ac87000 0 0x3000>;
		reg-names = "ipe0_top";
		reg-cam-base = <0x87000>;
		regulator-names = "ipe0-vdd";
		ipe0-vdd-supply = <&ipe_0_gdsc>;

		power-domains = <&clock_camcc IPE_0_GDSC>;
		clock-names = "ipe_0_ahb_clk",
			"ipe_0_areg_clk",
			"ipe_0_axi_clk",
			"ipe_0_clk",
			"ipe_0_clk_src";
		src-clock-name = "ipe_0_clk_src";
		clock-control-debugfs = "true";
		clocks = <&clock_camcc CAM_CC_IPE_0_AHB_CLK>,
				<&clock_camcc CAM_CC_IPE_0_AREG_CLK>,
				<&clock_camcc CAM_CC_IPE_0_AXI_CLK>,
				<&clock_camcc CAM_CC_IPE_0_CLK>,
				<&clock_camcc CAM_CC_IPE_0_CLK_SRC>;
		clock-rates =
			<0 0 0 0 404000000>,
			<0 0 0 0 480000000>,
			<0 0 0 0 538000000>,
			<0 0 0 0 600000000>;
		clock-cntl-level = "svs",
			"svs_l1", "nominal", "turbo";
		status = "ok";
	};

	cam_ipe1: qcom,ipe1 {
		cell-index = <1>;
		compatible = "qcom,cam-ipe";
		reg = <0 0x0ac91000 0 0x3000>;
		reg-names = "ipe1_top";
		reg-cam-base = <0x91000>;
		regulator-names = "ipe1-vdd";
		ipe1-vdd-supply = <&ipe_1_gdsc>;

		power-domains = <&clock_camcc IPE_1_GDSC>;
		clock-names = "ipe_1_ahb_clk",
			"ipe_1_areg_clk",
			"ipe_1_axi_clk",
			"ipe_1_clk",
			"ipe_1_clk_src";
		src-clock-name = "ipe_1_clk_src";
		clock-control-debugfs = "true";
		clocks = <&clock_camcc CAM_CC_IPE_1_AHB_CLK>,
				<&clock_camcc CAM_CC_IPE_1_AREG_CLK>,
				<&clock_camcc CAM_CC_IPE_1_AXI_CLK>,
				<&clock_camcc CAM_CC_IPE_1_CLK>,
				<&clock_camcc CAM_CC_IPE_1_CLK_SRC>;
		clock-rates =
			<0 0 0 0 404000000>,
			<0 0 0 0 480000000>,
			<0 0 0 0 538000000>,
			<0 0 0 0 600000000>;
		clock-cntl-level = "svs",
			"svs_l1", "nominal", "turbo";
		status = "ok";
	};

	cam_bps: qcom,bps {
		cell-index = <0>;
		compatible = "qcom,cam-bps";
		reg = <0 0x0ac6f000 0 0x3000>;
		reg-names = "bps_top";
		reg-cam-base = <0x6f000>;
		regulator-names = "bps-vdd";
		bps-vdd-supply = <&bps_gdsc>;

		power-domains = <&clock_camcc BPS_GDSC>;
		clock-names = "bps_ahb_clk",
			"bps_areg_clk",
			"bps_axi_clk",
			"bps_clk",
			"bps_clk_src";
		src-clock-name = "bps_clk_src";
		clock-control-debugfs = "true";
		clocks = <&clock_camcc CAM_CC_BPS_AHB_CLK>,
				<&clock_camcc CAM_CC_BPS_AREG_CLK>,
				<&clock_camcc CAM_CC_BPS_AXI_CLK>,
				<&clock_camcc CAM_CC_BPS_CLK>,
				<&clock_camcc CAM_CC_BPS_CLK_SRC>;
		clock-rates =
			<0 0 0 0 404000000>,
			<0 0 0 0 480000000>,
			<0 0 0 0 600000000>,
			<0 0 0 0 600000000>;
		clock-cntl-level = "svs",
			"svs_l1", "nominal", "turbo";
		status = "ok";
	};

	qcom,cam-jpeg {
		compatible = "qcom,cam-jpeg";
		compat-hw-name = "qcom,jpegenc",
			"qcom,jpegdma";
		num-jpeg-enc = <1>;
		num-jpeg-dma = <1>;
		status = "ok";
	};

	cam_jpeg_enc: qcom,jpegenc@ac4e000 {
		cell-index = <0>;
		compatible = "qcom,cam_jpeg_enc";
		reg-names = "jpege_hw";
		reg = <0 0x0ac4e000 0 0x4000>;
		reg-cam-base = <0x4e000>;
		interrupt-names = "jpeg";
		interrupts = <GIC_SPI 474 IRQ_TYPE_EDGE_RISING>;
		regulator-names = "camss-vdd";
		camss-vdd-supply = <&titan_top_gdsc>;
		clock-names = "camera_ahb",
			"camera_axi",
			"soc_ahb_clk",
			"cpas_ahb_clk",
			"camnoc_axi_clk",
			"jpegenc_clk_src",
			"jpegenc_clk";
		clocks = <&gcc GCC_CAMERA_AHB_CLK>,
			<&gcc GCC_CAMERA_AXI_CLK>,
			<&clock_camcc CAM_CC_SOC_AHB_CLK>,
			<&clock_camcc CAM_CC_CPAS_AHB_CLK>,
			<&clock_camcc CAM_CC_CAMNOC_AXI_CLK>,
			<&clock_camcc CAM_CC_JPEG_CLK_SRC>,
			<&clock_camcc CAM_CC_JPEG_CLK>;
		clock-rates = <0 0 0 0 0 600000000 0>;
		src-clock-name = "jpegenc_clk_src";
		clock-cntl-level = "nominal";
		status = "ok";
	};

	cam_jpeg_dma: qcom,jpegdma@ac52000 {
		cell-index = <0>;
		compatible = "qcom,cam_jpeg_dma";
		reg-names = "jpegdma_hw";
		reg = <0 0x0ac52000 0 0x4000>;
		reg-cam-base = <0x52000>;
		interrupt-names = "jpegdma";
		interrupts = <GIC_SPI 475 IRQ_TYPE_EDGE_RISING>;
		regulator-names = "camss-vdd";
		camss-vdd-supply = <&titan_top_gdsc>;
		clock-names = "camera_ahb",
			"camera_axi",
			"soc_ahb_clk",
			"cpas_ahb_clk",
			"camnoc_axi_clk",
			"jpegdma_clk_src",
			"jpegdma_clk";
		clocks = <&gcc GCC_CAMERA_AHB_CLK>,
			<&gcc GCC_CAMERA_AXI_CLK>,
			<&clock_camcc CAM_CC_SOC_AHB_CLK>,
			<&clock_camcc CAM_CC_CPAS_AHB_CLK>,
			<&clock_camcc CAM_CC_CAMNOC_AXI_CLK>,
			<&clock_camcc CAM_CC_JPEG_CLK_SRC>,
			<&clock_camcc CAM_CC_JPEG_CLK>;
		clock-rates = <0 0 0 0 0 600000000 0>;
		src-clock-name = "jpegdma_clk_src";
		clock-cntl-level = "nominal";
		status = "ok";
	};

	qcom,cam-fd {
		compatible = "qcom,cam-fd";
		compat-hw-name = "qcom,fd";
		num-fd = <1>;
		status = "ok";
	};

	cam_fd: qcom,fd@ac5a000 {
		cell-index = <0>;
		compatible = "qcom,fd41";
		reg-names = "fd_core", "fd_wrapper";
		reg = <0 0x0ac5a000 0 0x1000>,
			<0 0x0ac5b000 0 0x400>;
		reg-cam-base = <0x5a000 0x5b000>;
		interrupt-names = "fd";
		interrupts = <GIC_SPI 462 IRQ_TYPE_EDGE_RISING>;
		regulator-names = "camss-vdd";
		camss-vdd-supply = <&titan_top_gdsc>;
		clock-names = "gcc_ahb_clk",
			"gcc_axi_clk",
			"soc_ahb_clk",
			"cpas_ahb_clk",
			"camnoc_axi_clk",
			"fd_core_clk_src",
			"fd_core_clk",
			"fd_core_uar_clk";
		clocks = <&gcc GCC_CAMERA_AHB_CLK>,
			<&gcc GCC_CAMERA_AXI_CLK>,
			<&clock_camcc CAM_CC_SOC_AHB_CLK>,
			<&clock_camcc CAM_CC_CPAS_AHB_CLK>,
			<&clock_camcc CAM_CC_CAMNOC_AXI_CLK>,
			<&clock_camcc CAM_CC_FD_CORE_CLK_SRC>,
			<&clock_camcc CAM_CC_FD_CORE_CLK>,
			<&clock_camcc CAM_CC_FD_CORE_UAR_CLK>;
		src-clock-name = "fd_core_clk_src";
		clock-control-debugfs = "true";
		clock-cntl-level = "svs", "svs_l1", "turbo";
		clock-rates =
			<0 0 0 0 0 400000000 0 0>,
			<0 0 0 0 0 538000000 0 0>,
			<0 0 0 0 0 600000000 0 0>;
		status = "ok";
	};
};

&cam_cci {
	qcom,cam-res-mgr {
		compatible = "qcom,cam-res-mgr";
		status = "ok";

		gpios = <&tlmm 8 GPIO_ACTIVE_HIGH>;
		pinctrl-names = "cam_res_mgr_default", "cam_res_mgr_suspend";
		pinctrl-0 = <&cam_res_mgr_active>;
		pinctrl-1 = <&cam_res_mgr_suspend>;
	};

	qcom,cam-sensor@0 {
		cell-index = <0>;
		compatible = "qcom,cam-sensor";
		reg = <0x0>;
		csiphy-sd-index = <0>;
		sensor-position-roll = <180>;
		sensor-position-pitch = <0>;
		sensor-position-yaw = <0>;
		cam_vio-supply = <&vreg_lvs1a_1p8>;
		cam_vana-supply = <&vreg_bob>;
		cam_vdig-supply = <&camera_rear_ldo>;
		cam_clk-supply = <&titan_top_gdsc>;
		regulator-names = "cam_vio", "cam_vana", "cam_vdig", "cam_clk";
		rgltr-cntrl-support;
		rgltr-min-voltage = <0 3312000 1050000 0>;
		rgltr-max-voltage = <0 3600000 1050000 0>;
		rgltr-load-current = <0 80000 105000 0>;
		gpio-no-mux = <0>;
		gpios = <&tlmm 13 0>,
			<&tlmm 9 0>,
			<&tlmm 8 0>;
		gpio-reset = <1>;
		gpio-vana = <2>;
		gpio-req-tbl-num = <0 1 2>;
		gpio-req-tbl-flags = <1 0 0>;
		gpio-req-tbl-label = "CAMIF_MCLK0", "CAM_RESET0", "CAM_VANA0";
		sensor-mode = <0>;
		cci-master = <0>;
		status = "ok";
		clocks = <&clock_camcc CAM_CC_MCLK0_CLK>;
		clock-names = "cam_clk";
		clock-cntl-level = "turbo";
		clock-rates = <24000000>;
	};

	qcom,cam-sensor@1 {
		cell-index = <1>;
		compatible = "qcom,cam-sensor";
		reg = <0x1>;
		csiphy-sd-index = <1>;
		sensor-position-roll = <180>;
		sensor-position-pitch = <0>;
		sensor-position-yaw = <0>;
		cam_vio-supply = <&vreg_lvs1a_1p8>;
		cam_vana-supply = <&vreg_bob>;
		cam_vdig-supply = <&camera_rear_ldo>;
		cam_clk-supply = <&titan_top_gdsc>;
		regulator-names = "cam_vio", "cam_vana", "cam_vdig", "cam_clk";
		rgltr-cntrl-support;
		rgltr-min-voltage = <0 3312000 1050000 0>;
		rgltr-max-voltage = <0 3600000 1050000 0>;
		rgltr-load-current = <0 80000 105000 0>;
		gpio-no-mux = <0>;
		gpios = <&tlmm 14 0>,
			<&tlmm 7 0>,
			<&tlmm 8 0>;
		gpio-reset = <1>;
		gpio-vana = <2>;
		gpio-req-tbl-num = <0 1 2>;
		gpio-req-tbl-flags = <1 0 0>;
		gpio-req-tbl-label = "CAMIF_MCLK1", "CAM_RESET1", "CAM_VANA1";
		sensor-mode = <0>;
		cci-master = <0>;
		status = "ok";
		clocks = <&clock_camcc CAM_CC_MCLK1_CLK>;
		clock-names = "cam_clk";
		clock-cntl-level = "turbo";
		clock-rates = <24000000>;
	};

	qcom,cam-sensor@2 {
		cell-index = <2>;
		compatible = "qcom,cam-sensor";
		reg = <0x02>;
		csiphy-sd-index = <2>;
		sensor-position-roll = <180>;
		sensor-position-pitch = <0>;
		sensor-position-yaw = <0>;
		cam_vio-supply = <&vreg_lvs1a_1p8>;
		cam_vana-supply = <&vreg_bob>;
		cam_vdig-supply = <&camera_rear_ldo>;
		cam_clk-supply = <&titan_top_gdsc>;
		regulator-names = "cam_vio", "cam_vana", "cam_vdig", "cam_clk";
		rgltr-cntrl-support;
		rgltr-min-voltage = <0 3312000 1050000 0>;
		rgltr-max-voltage = <0 3600000 1050000 0>;
		rgltr-load-current = <0 80000 105000 0>;
		gpio-no-mux = <0>;
		gpios = <&tlmm 15 0>,
			<&tlmm 12 0>,
			<&tlmm 8 0>;
		gpio-reset = <1>;
		gpio-vana = <2>;
		gpio-req-tbl-num = <0 1 2>;
		gpio-req-tbl-flags = <1 0 0>;
		gpio-req-tbl-label = "CAMIF_MCLK2", "CAM_RESET2", "CAM_VANA2";
		sensor-mode = <0>;
		cci-master = <1>;
		status = "ok";
		clocks = <&clock_camcc CAM_CC_MCLK2_CLK>;
		clock-names = "cam_clk";
		clock-cntl-level = "turbo";
		clock-rates = <24000000>;
	};


};
